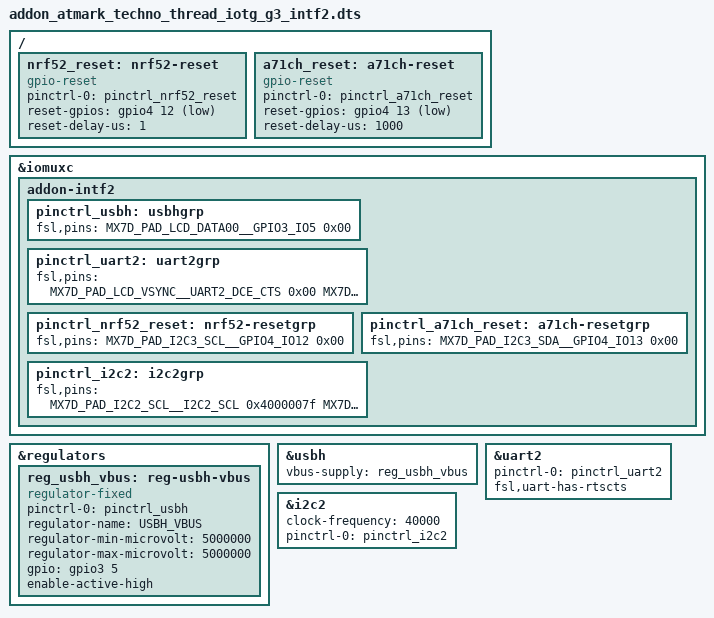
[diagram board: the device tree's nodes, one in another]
/*
 * Copyright (C) 2019 Atmark Techno, Inc. All Rights Reserved.
 * Author: Takumi Ando <takumi.ando@atmark-techno.com>
 *
 * This program is free software; you can redistribute it and/or
 * modify it under the terms of the GNU General Public License
 * version 2 as published by the Free Software Foundation.
 */

#include <dt-bindings/clock/imx7d-clock.h>
#include "../../../../arch/arm/boot/dts/imx7d-pinfunc.h"

/dts-v1/;
/plugin/;
/ {
	fragment@0 {
		target = <&iomuxc>;
		__overlay__ {
			addon-intf2 {
				pinctrl_usbh: usbhgrp {
					fsl,pins = <
						MX7D_PAD_LCD_DATA00__GPIO3_IO5 0x00	/* GPIO_AOM2_VBUS_PWREN */
					>;
				};
				pinctrl_uart2: uart2grp {
					fsl,pins = <
						MX7D_PAD_LCD_VSYNC__UART2_DCE_CTS	0x00	/* INTF2_38 */
						MX7D_PAD_LCD_HSYNC__UART2_DCE_RTS	0x10	/* INTF2_39 */
						MX7D_PAD_LCD_ENABLE__UART2_DCE_TX	0x00	/* INTF2_40 */
						MX7D_PAD_LCD_CLK__UART2_DCE_RX		0x70	/* INTF2_41 */
					>;
				};
				pinctrl_nrf52_reset: nrf52-resetgrp {
					fsl,pins = <
						MX7D_PAD_I2C3_SCL__GPIO4_IO12		0x00    /* INTF2_42 */
					>;
				};
				pinctrl_a71ch_reset: a71ch-resetgrp {
					fsl,pins = <
						MX7D_PAD_I2C3_SDA__GPIO4_IO13		0x00    /* INTF2_43 */
					>;
				};
				pinctrl_i2c2: i2c2grp {
					fsl,pins = <
						MX7D_PAD_I2C2_SCL__I2C2_SCL	0x4000007f	/* INTF2_24 */
						MX7D_PAD_I2C2_SDA__I2C2_SDA	0x4000007f	/* INTF2_25 */
					>;
				};
			};
		};
	};

	fragment@1 {
		target = <&regulators>;
		__overlay__ {
			reg_usbh_vbus: reg-usbh-vbus {
				compatible = "regulator-fixed";
				pinctrl-names = "default";
				pinctrl-0 = <&pinctrl_usbh>;
				regulator-name = "USBH_VBUS";
				regulator-min-microvolt = <5000000>;
				regulator-max-microvolt = <5000000>;
				gpio = <&gpio3 5 0>;
				enable-active-high;
			};
		};
	};

	fragment@2 {
		target = <&usbh>;
		__overlay__ {
			vbus-supply = <&reg_usbh_vbus>;
		};
	};

	fragment@3 {
		target = <&uart2>;
		__overlay__ {
			pinctrl-names = "default";
			pinctrl-0 = <&pinctrl_uart2>;
			fsl,uart-has-rtscts;
			status = "okay";
		};
	};

	fragment@4 {
		target-path = "/";
		__overlay__ {
			nrf52_reset: nrf52-reset {
				compatible = "gpio-reset";
				pinctrl-0 = <&pinctrl_nrf52_reset>;
				reset-gpios = <&gpio4 12 1>;
				reset-delay-us = <1>;
				#reset-cells = <0>;
			};

			a71ch_reset: a71ch-reset {
				compatible = "gpio-reset";
				pinctrl-0 = <&pinctrl_a71ch_reset>;
				reset-gpios = <&gpio4 13 1>;
				reset-delay-us = <1000>;
				#reset-cells = <0>;
			};
		};
	};

	fragment@5 {
		target = <&i2c2>;
		__overlay__ {
			clock-frequency = <40000>;
			pinctrl-names = "default";
			pinctrl-0 = <&pinctrl_i2c2>;
			status = "okay";
		};
	};
};
